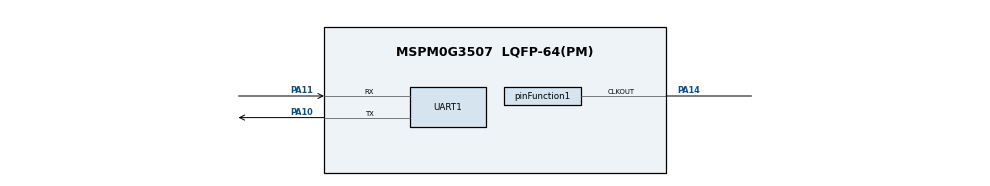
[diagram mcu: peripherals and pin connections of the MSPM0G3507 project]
/**
 * These arguments were used when this file was generated. They will be automatically applied on subsequent loads
 * via the GUI or CLI. Run CLI with '--help' for additional information on how to override these arguments.
 * @cliArgs --device "MSPM0G350X" --part "Default" --package "LQFP-64(PM)" --product "mspm0_sdk@2.02.00.05"
 * @v2CliArgs --device "MSPM0G3507" --package "LQFP-64(PM)" --product "mspm0_sdk@2.02.00.05"
 * @versions {"tool":"1.21.0+3721"}
 */

/**
 * Import the modules used in this configuration.
 */
const ADC12   = scripting.addModule("/ti/driverlib/ADC12", {}, false);
const ADC121  = ADC12.addInstance();
const ADC122  = ADC12.addInstance();
const CRC     = scripting.addModule("/ti/driverlib/CRC");
const GPIO    = scripting.addModule("/ti/driverlib/GPIO", {}, false);
const GPIO1   = GPIO.addInstance();
const GPIO2   = GPIO.addInstance();
const SYSCTL  = scripting.addModule("/ti/driverlib/SYSCTL");
const SYSTICK = scripting.addModule("/ti/driverlib/SYSTICK");
const TIMER   = scripting.addModule("/ti/driverlib/TIMER", {}, false);
const TIMER1  = TIMER.addInstance();
const UART    = scripting.addModule("/ti/driverlib/UART", {}, false);
const UART1   = UART.addInstance();

/**
 * Write custom configuration values to the imported modules.
 */
const divider5       = system.clockTree["PLL_CLK1_DIV"];
divider5.divideValue = 4;

const divider6       = system.clockTree["PLL_CLK2X_DIV"];
divider6.divideValue = 4;

const divider7       = system.clockTree["PLL_PDIV"];
divider7.divideValue = 2;

const divider9       = system.clockTree["UDIV"];
divider9.divideValue = 2;

const gate4  = system.clockTree["EXCLKGATE"];
gate4.enable = true;

const multiplier2         = system.clockTree["PLL_QDIV"];
multiplier2.multiplyValue = 10;

const mux3       = system.clockTree["EXCLKMUX"];
mux3.inputSelect = "EXCLKMUX_PLLCLK1_OUT";

const mux8       = system.clockTree["HSCLKMUX"];
mux8.inputSelect = "HSCLKMUX_SYSPLL2X";

const pinFunction1                        = system.clockTree["CLKOUT"];
pinFunction1.enable                       = true;
pinFunction1.peripheral.clkOutPin.$assign = "PA14";

ADC121.$name               = "ADC12_0";
ADC121.sampClkSrc          = "DL_ADC12_CLOCK_ULPCLK";
ADC121.sampClkDiv          = "DL_ADC12_CLOCK_DIVIDE_32";
ADC121.repeatMode          = true;
ADC121.trigSrc             = "DL_ADC12_TRIG_SRC_EVENT";
ADC121.adcMem0chansel      = "DL_ADC12_INPUT_CHAN_3";
ADC121.adcMem0avgen        = true;
ADC121.enabledInterrupts   = ["DL_ADC12_INTERRUPT_MEM0_RESULT_LOADED"];
ADC121.subChanID           = 1;
ADC121.adcMem0trig         = "DL_ADC12_TRIGGER_MODE_TRIGGER_NEXT";
ADC121.interruptPriority   = "2";
ADC121.sampleTime0         = "300 us";
ADC121.hwNumerator         = "DL_ADC12_HW_AVG_NUM_ACC_16";
ADC121.hwDenominator       = "DL_ADC12_HW_AVG_DEN_DIV_BY_16";
ADC121.peripheral.$assign  = "ADC0";
ADC121.adcPin3Config.$name = "ti_driverlib_gpio_GPIOPinGeneric2";

ADC122.$name               = "ADC12_1";
ADC122.sampClkSrc          = "DL_ADC12_CLOCK_ULPCLK";
ADC122.sampClkDiv          = "DL_ADC12_CLOCK_DIVIDE_32";
ADC122.repeatMode          = true;
ADC122.trigSrc             = "DL_ADC12_TRIG_SRC_EVENT";
ADC122.adcMem0chansel      = "DL_ADC12_INPUT_CHAN_2";
ADC122.adcMem0avgen        = true;
ADC122.hwNumerator         = "DL_ADC12_HW_AVG_NUM_ACC_32";
ADC122.hwDenominator       = "DL_ADC12_HW_AVG_DEN_DIV_BY_32";
ADC122.enabledInterrupts   = ["DL_ADC12_INTERRUPT_MEM0_RESULT_LOADED"];
ADC122.subChanID           = 2;
ADC122.adcMem0trig         = "DL_ADC12_TRIGGER_MODE_TRIGGER_NEXT";
ADC122.interruptPriority   = "2";
ADC122.sampleTime0         = "2 ms";
ADC122.peripheral.$assign  = "ADC1";
ADC122.adcPin2Config.$name = "ti_driverlib_gpio_GPIOPinGeneric3";

const Board = scripting.addModule("/ti/driverlib/Board", {}, false);

CRC.seed       = 0xFFFFFFFF;
CRC.bitReverse = "REVERSED";

GPIO1.$name                               = "GPIO_LEDS_A";
GPIO1.associatedPins[0].assignedPort      = "PORTA";
GPIO1.associatedPins[0].assignedPin       = "0";
GPIO1.associatedPins[0].launchPadShortcut = "LED1En";
GPIO1.associatedPins[0].$name             = "LED_1";

GPIO2.$name                               = "GPIO_LEDS_B";
GPIO2.associatedPins.create(3);
GPIO2.associatedPins[0].$name             = "LED_RED";
GPIO2.associatedPins[0].launchPadShortcut = "LED2RedEn";
GPIO2.associatedPins[1].launchPadShortcut = "LED2GreenEn";
GPIO2.associatedPins[1].$name             = "LED_GREEN";
GPIO2.associatedPins[2].$name             = "LED_BLUE";
GPIO2.associatedPins[2].launchPadShortcut = "LED2BlueEn";

SYSCTL.MCLKSource            = "HSCLK";
SYSCTL.EXCLKSource           = "SYSPLLOUT1";
SYSCTL.SYSPLL_CLK1En         = true;
SYSCTL.enableEXCLK           = true;
SYSCTL.SYSPLL_CLK2XEn        = true;
SYSCTL.SYSPLL_CLK2XDiv       = 1;
SYSCTL.HSCLKSource           = "SYSPLLCLK2X";
SYSCTL.validateClkStatus     = true;
SYSCTL.SYSPLL_Qdiv           = 5;
SYSCTL.forceDefaultClkConfig = true;
SYSCTL.clockTreeEn           = true;

SYSTICK.periodEnable      = true;
SYSTICK.period            = 1600000;
SYSTICK.interruptEnable   = true;
SYSTICK.systickEnable     = true;
SYSTICK.interruptPriority = "1";

TIMER1.timerClkDiv                 = 8;
TIMER1.timerMode                   = "PERIODIC";
TIMER1.timerClkPrescale            = 200;
TIMER1.event1PublisherChannel      = 1;
TIMER1.event2PublisherChannel      = 2;
TIMER1.$name                       = "VOLT_TIMER";
TIMER1.timerPeriod                 = "1 s";
TIMER1.event1ControllerInterruptEn = ["LOAD_EVENT"];
TIMER1.event2ControllerInterruptEn = ["LOAD_EVENT"];
TIMER1.peripheral.$assign          = "TIMA0";

UART1.$name                             = "TERMINAL_UART";
UART1.targetBaudRate                    = 1000000;
UART1.enableFIFO                        = true;
UART1.rxFifoThreshold                   = "DL_UART_RX_FIFO_LEVEL_ONE_ENTRY";
UART1.txFifoThreshold                   = "DL_UART_TX_FIFO_LEVEL_3_4_EMPTY";
UART1.enabledInterrupts                 = ["DMA_DONE_RX","DMA_DONE_TX"];
UART1.enabledDMARXTriggers              = "DL_UART_DMA_INTERRUPT_RX";
UART1.enabledDMATXTriggers              = "DL_UART_DMA_INTERRUPT_TX";
UART1.interruptPriority                 = "2";
UART1.peripheral.$assign                = "UART0";
UART1.peripheral.rxPin.$assign          = "PA11";
UART1.peripheral.txPin.$assign          = "PA10";
UART1.txPinConfig.direction             = scripting.forceWrite("OUTPUT");
UART1.txPinConfig.hideOutputInversion   = scripting.forceWrite(false);
UART1.txPinConfig.onlyInternalResistor  = scripting.forceWrite(false);
UART1.txPinConfig.passedPeripheralType  = scripting.forceWrite("Digital");
UART1.txPinConfig.$name                 = "ti_driverlib_gpio_GPIOPinGeneric0";
UART1.rxPinConfig.hideOutputInversion   = scripting.forceWrite(false);
UART1.rxPinConfig.onlyInternalResistor  = scripting.forceWrite(false);
UART1.rxPinConfig.passedPeripheralType  = scripting.forceWrite("Digital");
UART1.rxPinConfig.$name                 = "ti_driverlib_gpio_GPIOPinGeneric1";
UART1.DMA_CHANNEL_RX.$name              = "DMA_CH_RX";
UART1.DMA_CHANNEL_RX.addressMode        = "f2b";
UART1.DMA_CHANNEL_RX.srcLength          = "BYTE";
UART1.DMA_CHANNEL_RX.dstLength          = "BYTE";
UART1.DMA_CHANNEL_RX.enableInterrupt    = true;
UART1.DMA_CHANNEL_RX.peripheral.$assign = "DMA_CH3";
UART1.DMA_CHANNEL_TX.$name              = "DMA_CH_TX";
UART1.DMA_CHANNEL_TX.addressMode        = "b2f";
UART1.DMA_CHANNEL_TX.srcLength          = "BYTE";
UART1.DMA_CHANNEL_TX.dstLength          = "BYTE";
UART1.DMA_CHANNEL_TX.enableInterrupt    = true;
UART1.DMA_CHANNEL_TX.peripheral.$assign = "DMA_CH4";

/**
 * Pinmux solution for unlocked pins/peripherals. This ensures that minor changes to the automatic solver in a future
 * version of the tool will not impact the pinmux you originally saw.  These lines can be completely deleted in order to
 * re-solve from scratch.
 */
pinFunction1.peripheral.$suggestSolution     = "SYSCTL";
ADC121.peripheral.adcPin3.$suggestSolution   = "PA24";
ADC122.peripheral.adcPin2.$suggestSolution   = "PA17";
Board.peripheral.$suggestSolution            = "DEBUGSS";
Board.peripheral.swclkPin.$suggestSolution   = "PA20";
Board.peripheral.swdioPin.$suggestSolution   = "PA19";
GPIO1.associatedPins[0].pin.$suggestSolution = "PA0";
GPIO2.associatedPins[0].pin.$suggestSolution = "PB26";
GPIO2.associatedPins[1].pin.$suggestSolution = "PB27";
GPIO2.associatedPins[2].pin.$suggestSolution = "PB22";
